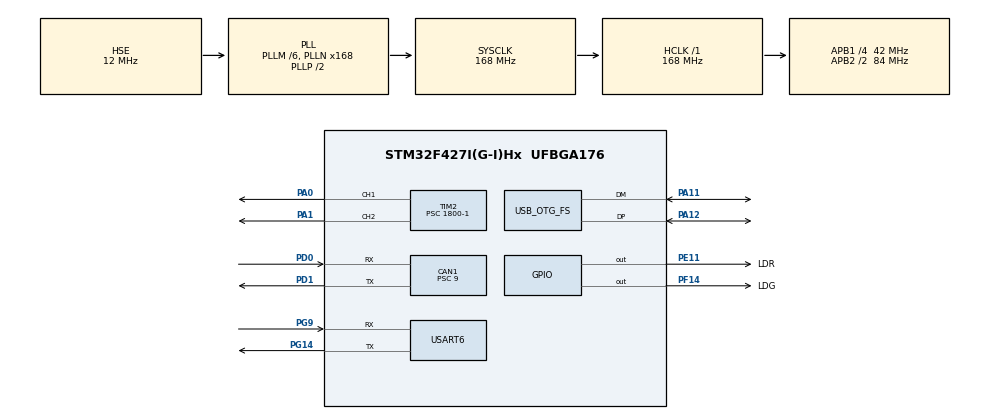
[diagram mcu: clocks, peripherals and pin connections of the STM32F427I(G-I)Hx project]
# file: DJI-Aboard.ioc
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CAN1.ABOM=DISABLE
CAN1.AWUM=DISABLE
CAN1.BS1=CAN_BS1_3TQ
CAN1.BS2=CAN_BS2_1TQ
CAN1.CalculateBaudRate=933333
CAN1.CalculateTimeBit=1071
CAN1.CalculateTimeQuantum=214.28571428571428
CAN1.Mode=CAN_MODE_NORMAL
CAN1.NART=DISABLE
CAN1.Prescaler=9
CAN1.RFLM=DISABLE
CAN1.SJW=CAN_SJW_1TQ
CAN1.TTCM=DISABLE
CAN1.TXFP=DISABLE
Dma.Request0=USART6_RX
Dma.Request1=USART6_TX
Dma.USART6_RX.0.Direction=DMA_PERIPH_TO_MEMORY
Dma.USART6_RX.0.FIFOMode=DMA_FIFOMODE_DISABLE
Dma.USART6_RX.0.Instance=DMA2_Stream1
Dma.USART6_RX.0.MemDataAlignment=DMA_MDATAALIGN_BYTE
Dma.USART6_RX.0.MemInc=DMA_MINC_ENABLE
Dma.USART6_RX.0.Mode=DMA_CIRCULAR
Dma.USART6_RX.0.PeriphDataAlignment=DMA_PDATAALIGN_BYTE
Dma.USART6_RX.0.PeriphInc=DMA_PINC_DISABLE
Dma.USART6_RX.0.Priority=DMA_PRIORITY_VERY_HIGH
Dma.USART6_TX.1.Direction=DMA_MEMORY_TO_PERIPH
Dma.USART6_TX.1.FIFOMode=DMA_FIFOMODE_DISABLE
Dma.USART6_TX.1.Instance=DMA2_Stream6
Dma.USART6_TX.1.MemDataAlignment=DMA_MDATAALIGN_BYTE
Dma.USART6_TX.1.MemInc=DMA_MINC_ENABLE
Dma.USART6_TX.1.Mode=DMA_NORMAL
Dma.USART6_TX.1.PeriphDataAlignment=DMA_PDATAALIGN_BYTE
Dma.USART6_TX.1.PeriphInc=DMA_PINC_DISABLE
Dma.USART6_TX.1.Priority=DMA_PRIORITY_VERY_HIGH
FREERTOS.Tasks01=defaultTask,24,3000,StartDefaultTask,Default,NULL,Dynamic,NULL,NULL
FREERTOS.configENABLE_FPU=1
Mcu.Family=STM32F4
Mcu.Name=STM32F427I(G-I)Hx
Mcu.Package=UFBGA176
NVIC.CAN1_RX0_IRQn=true\:5\:0\:false\:false\:true\:true\:true\:true\:true
NVIC.DMA2_Stream1_IRQn=true\:5\:0\:false\:false\:true\:true\:false\:true\:true
NVIC.DMA2_Stream6_IRQn=true\:5\:0\:false\:false\:true\:true\:false\:true\:true
NVIC.OTG_FS_IRQn=true\:5\:0\:false\:false\:true\:true\:false\:true\:true
NVIC.PriorityGroup=NVIC_PRIORITYGROUP_4
NVIC.TIM1_UP_TIM10_IRQn=true\:15\:0\:false\:false\:true\:false\:false\:true\:true
NVIC.TimeBase=TIM1_UP_TIM10_IRQn
NVIC.TimeBaseIP=TIM1
NVIC.USART6_IRQn=true\:5\:0\:false\:false\:true\:true\:true\:true\:true
PA0/WKUP.Signal=S_TIM2_CH1_ETR
PA1.Signal=S_TIM2_CH2
PA11.Mode=Device_Only
PA11.Signal=USB_OTG_FS_DM
PA12.Mode=Device_Only
PA12.Signal=USB_OTG_FS_DP
PA13.Mode=Serial_Wire
PA13.Signal=SYS_JTMS-SWDIO
PA14.Mode=Serial_Wire
PA14.Signal=SYS_JTCK-SWCLK
PC14/OSC32_IN.Mode=LSE-External-Clock-Source
PC14/OSC32_IN.Signal=RCC_OSC32_IN
PC15/OSC32_OUT.Mode=LSE-External-Clock-Source
PC15/OSC32_OUT.Signal=RCC_OSC32_OUT
PD0.Mode=CAN_Activate
PD0.Signal=CAN1_RX
PD1.Mode=CAN_Activate
PD1.Signal=CAN1_TX
PE11.GPIO_Label=LDR
PE11.PinState=GPIO_PIN_SET
PE11.Signal=GPIO_Output
PF14.GPIO_Label=LDG
PF14.PinState=GPIO_PIN_SET
PF14.Signal=GPIO_Output
PG14.Mode=Asynchronous
PG14.Signal=USART6_TX
PG9.Mode=Asynchronous
PG9.Signal=USART6_RX
PH0/OSC_IN.Mode=HSE-External-Oscillator
PH0/OSC_IN.Signal=RCC_OSC_IN
PH1/OSC_OUT.Mode=HSE-External-Oscillator
PH1/OSC_OUT.Signal=RCC_OSC_OUT
ProjectManager.HeapSize=0x200
ProjectManager.StackSize=0x400
ProjectManager.TargetToolchain=STM32CubeIDE
RCC.48MHZClocksFreq_Value=48000000
RCC.AHBFreq_Value=168000000
RCC.APB1CLKDivider=RCC_HCLK_DIV4
RCC.APB1Freq_Value=42000000
RCC.APB1TimFreq_Value=84000000
RCC.APB2CLKDivider=RCC_HCLK_DIV2
RCC.APB2Freq_Value=84000000
RCC.APB2TimFreq_Value=168000000
RCC.CortexFreq_Value=168000000
RCC.FLatency=FLASH_LATENCY_5
RCC.HCLKFreq_Value=168000000
RCC.HSE_VALUE=12000000
RCC.HSI_VALUE=16000000
RCC.LSE_VALUE=32768
RCC.PLLM=6
RCC.PLLN=168
RCC.PLLQ=7
RCC.PWREXT_OverDrive=PWREXT_OverDrive_ACTIVATED
RCC.PWR_Regulator_Voltage_Scale=PWR_REGULATOR_VOLTAGE_SCALE1
RCC.SYSCLKFreq_VALUE=168000000
RCC.SYSCLKSource=RCC_SYSCLKSOURCE_PLLCLK
RCC.VCOOutputFreq_Value=336000000
SH.S_TIM2_CH1_ETR.0=TIM2_CH1,PWM Generation1 CH1
SH.S_TIM2_CH2.0=TIM2_CH2,PWM Generation2 CH2
TIM2.AutoReloadPreload=TIM_AUTORELOAD_PRELOAD_ENABLE
TIM2.Channel-PWM\ Generation1\ CH1=TIM_CHANNEL_1
TIM2.Channel-PWM\ Generation2\ CH2=TIM_CHANNEL_2
TIM2.Period=1000-1
TIM2.Prescaler=1800-1
USART6.VirtualMode=VM_ASYNC
USB_DEVICE.CLASS_NAME_FS=CDC
USB_DEVICE.VirtualMode-CDC_FS=Cdc
USB_DEVICE.VirtualModeFS=Cdc_FS
USB_OTG_FS.VirtualMode=Device_Only
VP_FREERTOS_VS_CMSIS_V2.Mode=CMSIS_V2
VP_SYS_VS_tim1.Mode=TIM1
VP_TIM2_VS_ClockSourceINT.Mode=Internal
VP_USB_DEVICE_VS_USB_DEVICE_CDC_FS.Mode=CDC_FS
board=custom

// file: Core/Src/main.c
/* USER CODE BEGIN Header */
/**
  ******************************************************************************
  * @file           : main.c
  * @brief          : Main program body
  ******************************************************************************
  * @attention
  *
  * Copyright (c) 2023 STMicroelectronics.
  * All rights reserved.
  *
  * This software is licensed under terms that can be found in the LICENSE file
  * in the root directory of this software component.
  * If no LICENSE file comes with this software, it is provided AS-IS.
  *
  ******************************************************************************
  */
/* USER CODE END Header */
#include "main.h"
#include "cmsis_os.h"
#include "can.h"
#include "dma.h"
#include "tim.h"
#include "usart.h"
#include "usb_device.h"
#include "gpio.h"

/* USER CODE BEGIN Includes */

#include "retarget.h"
/* USER CODE END Includes */

void SystemClock_Config(void);
void MX_FREERTOS_Init(void);

int main(void)
{

  /* MCU Configuration--------------------------------------------------------*/

  /* Reset of all peripherals, Initializes the Flash interface and the Systick. */
  HAL_Init();

  /* Configure the system clock */
  SystemClock_Config();

  /* Initialize all configured peripherals */
  MX_GPIO_Init();
  MX_DMA_Init();
  MX_CAN1_Init();
  MX_USART6_UART_Init();
  MX_TIM2_Init();
  /* USER CODE BEGIN 2 */
    RetargetInit(&huart6);
    HAL_Delay(200);

  /* USER CODE END 2 */

  /* Init scheduler */
  osKernelInitialize();  /* Call init function for freertos objects (in freertos.c) */
  MX_FREERTOS_Init();

  /* Start scheduler */
  osKernelStart();

  /* We should never get here as control is now taken by the scheduler */
  /* Infinite loop */
  while (1)
  {

  }
}

void SystemClock_Config(void)
{
  RCC_OscInitTypeDef RCC_OscInitStruct = {0};
  RCC_ClkInitTypeDef RCC_ClkInitStruct = {0};

  /** Configure the main internal regulator output voltage
  */
  __HAL_RCC_PWR_CLK_ENABLE();
  __HAL_PWR_VOLTAGESCALING_CONFIG(PWR_REGULATOR_VOLTAGE_SCALE1);

  /** Initializes the RCC Oscillators according to the specified parameters
  * in the RCC_OscInitTypeDef structure.
  */
  RCC_OscInitStruct.OscillatorType = RCC_OSCILLATORTYPE_HSE;
  RCC_OscInitStruct.HSEState = RCC_HSE_ON;
  RCC_OscInitStruct.PLL.PLLState = RCC_PLL_ON;
  RCC_OscInitStruct.PLL.PLLSource = RCC_PLLSOURCE_HSE;
  RCC_OscInitStruct.PLL.PLLM = 6;
  RCC_OscInitStruct.PLL.PLLN = 168;
  RCC_OscInitStruct.PLL.PLLP = RCC_PLLP_DIV2;
  RCC_OscInitStruct.PLL.PLLQ = 7;
  if (HAL_RCC_OscConfig(&RCC_OscInitStruct) != HAL_OK)
  {
    Error_Handler();
  }

  /** Activate the Over-Drive mode
  */
  if (HAL_PWREx_EnableOverDrive() != HAL_OK)
  {
    Error_Handler();
  }

  /** Initializes the CPU, AHB and APB buses clocks
  */
  RCC_ClkInitStruct.ClockType = RCC_CLOCKTYPE_HCLK|RCC_CLOCKTYPE_SYSCLK
                              |RCC_CLOCKTYPE_PCLK1|RCC_CLOCKTYPE_PCLK2;
  RCC_ClkInitStruct.SYSCLKSource = RCC_SYSCLKSOURCE_PLLCLK;
  RCC_ClkInitStruct.AHBCLKDivider = RCC_SYSCLK_DIV1;
  RCC_ClkInitStruct.APB1CLKDivider = RCC_HCLK_DIV4;
  RCC_ClkInitStruct.APB2CLKDivider = RCC_HCLK_DIV2;

  if (HAL_RCC_ClockConfig(&RCC_ClkInitStruct, FLASH_LATENCY_5) != HAL_OK)
  {
    Error_Handler();
  }
}

void HAL_TIM_PeriodElapsedCallback(TIM_HandleTypeDef *htim)
{
  if (htim->Instance == TIM1) {
    HAL_IncTick();
  }
}

void Error_Handler(void)
{
  __disable_irq();
  while (1)
  {
  }
}

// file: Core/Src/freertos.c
/* USER CODE BEGIN Header */
/**
  ******************************************************************************
  * File Name          : freertos.c
  * Description        : Code for freertos applications
  ******************************************************************************
  * @attention
  *
  * Copyright (c) 2023 STMicroelectronics.
  * All rights reserved.
  *
  * This software is licensed under terms that can be found in the LICENSE file
  * in the root directory of this software component.
  * If no LICENSE file comes with this software, it is provided AS-IS.
  *
  ******************************************************************************
  */
/* USER CODE END Header */

#include "FreeRTOS.h"
#include "task.h"
#include "main.h"
#include "cmsis_os.h"

/* USER CODE BEGIN Includes */
#include "usart.h"
#include "USER_main.h"
#include "tim.h"
/* USER CODE END Includes */

/* Definitions for defaultTask */
osThreadId_t defaultTaskHandle;
const osThreadAttr_t defaultTask_attributes = {
  .name = "defaultTask",
  .stack_size = 3000 * 4,
  .priority = (osPriority_t) osPriorityNormal,
};

void StartDefaultTask(void *argument);

extern void MX_USB_DEVICE_Init(void);
void MX_FREERTOS_Init(void); /* (MISRA C 2004 rule 8.1) */

void MX_FREERTOS_Init(void) {

  /* Create the thread(s) */
  /* creation of defaultTask */
  defaultTaskHandle = osThreadNew(StartDefaultTask, NULL, &defaultTask_attributes);

}

void StartDefaultTask(void *argument)
{
  /* init code for USB_DEVICE */
  MX_USB_DEVICE_Init();
  /* USER CODE BEGIN StartDefaultTask */
//    HAL_TIM_PWM_Start(&htim2, TIM_CHANNEL_1);
//    HAL_TIM_PWM_Start(&htim2, TIM_CHANNEL_2);
//    osDelay(10);

  //UserStartDefaultTask(argument);
  /* Infinite loop */
  for(;;)
  {
      HAL_GPIO_TogglePin(LDR_GPIO_Port, LDR_Pin);
      __HAL_TIM_SET_COMPARE(&htim2, TIM_CHANNEL_1, 25);
      __HAL_TIM_SET_COMPARE(&htim2, TIM_CHANNEL_2, 75);
      HAL_UART_Transmit(&huart6, (uint8_t*)"Hello World!\r\n", 14, 1000);
    osDelay(100);
  }
  /* USER CODE END StartDefaultTask */
}
